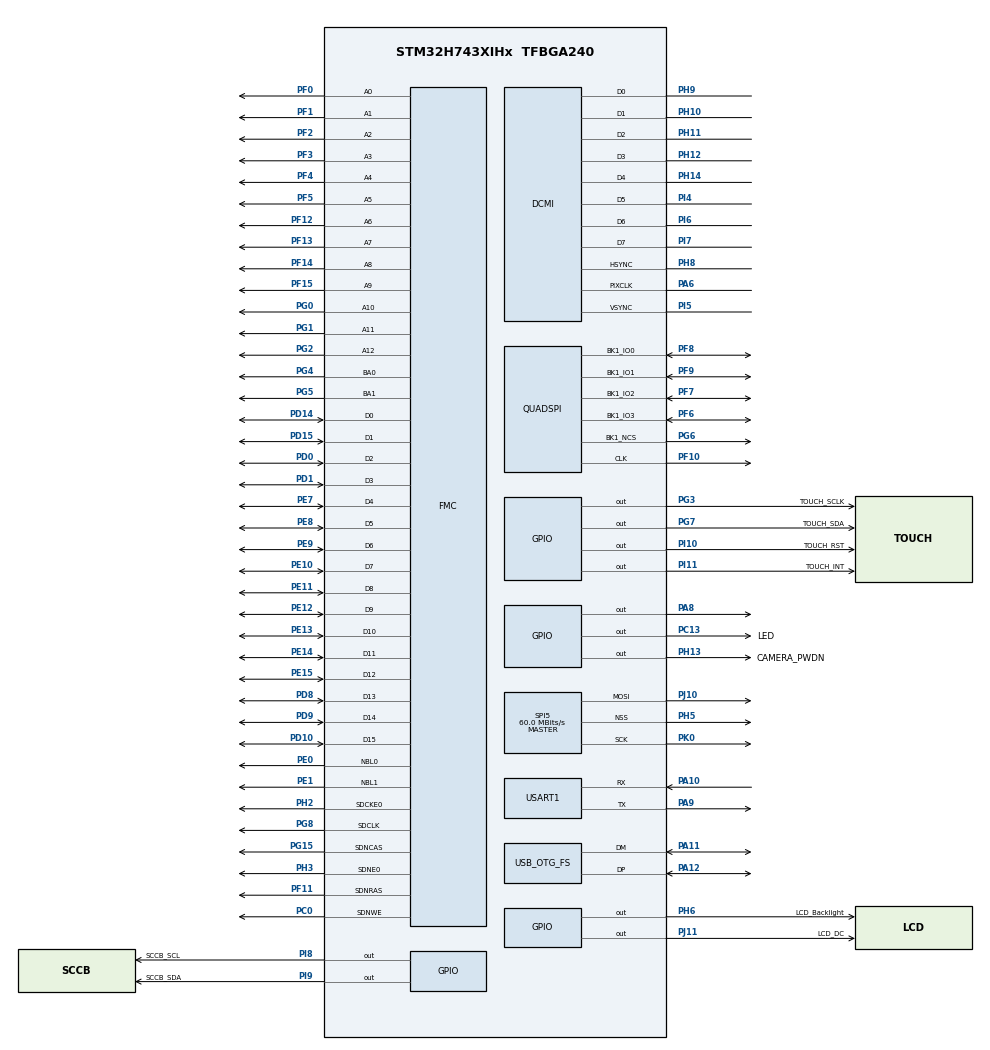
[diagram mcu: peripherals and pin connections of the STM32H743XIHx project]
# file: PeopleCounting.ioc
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ADC3.Channel-1\#ChannelRegularConversion=ADC_CHANNEL_VBAT
ADC3.Channel-2\#ChannelRegularConversion=ADC_CHANNEL_TEMPSENSOR
ADC3.Channel-3\#ChannelRegularConversion=ADC_CHANNEL_VREFINT
ADC3.ContinuousConvMode=ENABLE
ADC3.ConversionDataManagement=ADC_CONVERSIONDATA_DMA_CIRCULAR
ADC3.EOCSelection=ADC_EOC_SEQ_CONV
ADC3.EnableRegularConversion=ENABLE
ADC3.LeftBitShift=ADC_LEFTBITSHIFT_NONE
ADC3.NbrOfConversion=3
ADC3.NbrOfConversionFlag=1
ADC3.OffsetNumber-1\#ChannelRegularConversion=ADC_OFFSET_NONE
ADC3.OffsetNumber-2\#ChannelRegularConversion=ADC_OFFSET_NONE
ADC3.OffsetNumber-3\#ChannelRegularConversion=ADC_OFFSET_NONE
ADC3.OffsetSignedSaturation-1\#ChannelRegularConversion=DISABLE
ADC3.OffsetSignedSaturation-2\#ChannelRegularConversion=DISABLE
ADC3.OffsetSignedSaturation-3\#ChannelRegularConversion=DISABLE
ADC3.OversamplingMode=ENABLE
ADC3.Rank-1\#ChannelRegularConversion=1
ADC3.Rank-2\#ChannelRegularConversion=2
ADC3.Rank-3\#ChannelRegularConversion=3
ADC3.Ratio=1024
ADC3.Resolution=ADC_RESOLUTION_16B
ADC3.RightBitShift=ADC_RIGHTBITSHIFT_10
ADC3.SamplingTime-1\#ChannelRegularConversion=ADC_SAMPLETIME_810CYCLES_5
ADC3.SamplingTime-2\#ChannelRegularConversion=ADC_SAMPLETIME_810CYCLES_5
ADC3.SamplingTime-3\#ChannelRegularConversion=ADC_SAMPLETIME_810CYCLES_5
Bdma.ADC3.0.Direction=DMA_PERIPH_TO_MEMORY
Bdma.ADC3.0.EventEnable=DISABLE
Bdma.ADC3.0.Instance=BDMA_Channel0
Bdma.ADC3.0.MemDataAlignment=DMA_MDATAALIGN_HALFWORD
Bdma.ADC3.0.MemInc=DMA_MINC_ENABLE
Bdma.ADC3.0.Mode=DMA_CIRCULAR
Bdma.ADC3.0.PeriphDataAlignment=DMA_PDATAALIGN_HALFWORD
Bdma.ADC3.0.PeriphInc=DMA_PINC_DISABLE
Bdma.ADC3.0.Polarity=HAL_DMAMUX_REQ_GEN_RISING
Bdma.ADC3.0.Priority=DMA_PRIORITY_LOW
Bdma.ADC3.0.RequestNumber=1
Bdma.ADC3.0.SignalID=NONE
Bdma.ADC3.0.SyncEnable=DISABLE
Bdma.ADC3.0.SyncPolarity=HAL_DMAMUX_SYNC_NO_EVENT
Bdma.ADC3.0.SyncRequestNumber=1
Bdma.ADC3.0.SyncSignalID=NONE
Bdma.Request0=ADC3
Bdma.RequestsNb=1
CORTEX_M7.AccessPermission-Cortex_Memory_Protection_Unit_Region0_Settings=MPU_REGION_FULL_ACCESS
CORTEX_M7.AccessPermission-Cortex_Memory_Protection_Unit_Region1_Settings=MPU_REGION_FULL_ACCESS
CORTEX_M7.AccessPermission-Cortex_Memory_Protection_Unit_Region2_Settings=MPU_REGION_FULL_ACCESS
CORTEX_M7.AccessPermission-Cortex_Memory_Protection_Unit_Region3_Settings=MPU_REGION_FULL_ACCESS
CORTEX_M7.AccessPermission-Cortex_Memory_Protection_Unit_Region4_Settings=MPU_REGION_FULL_ACCESS
CORTEX_M7.AccessPermission-Cortex_Memory_Protection_Unit_Region5_Settings=MPU_REGION_FULL_ACCESS
CORTEX_M7.AccessPermission-Cortex_Memory_Protection_Unit_Region6_Settings=MPU_REGION_FULL_ACCESS
CORTEX_M7.AccessPermission-Cortex_Memory_Protection_Unit_Region7_Settings=MPU_REGION_FULL_ACCESS
CORTEX_M7.BaseAddress-Cortex_Memory_Protection_Unit_Region0_Settings=0x20000000
CORTEX_M7.BaseAddress-Cortex_Memory_Protection_Unit_Region1_Settings=0x24000000
CORTEX_M7.BaseAddress-Cortex_Memory_Protection_Unit_Region2_Settings=0x30000000
CORTEX_M7.BaseAddress-Cortex_Memory_Protection_Unit_Region3_Settings=0x38000000
CORTEX_M7.BaseAddress-Cortex_Memory_Protection_Unit_Region5_Settings=0xC0000000
CORTEX_M7.BaseAddress-Cortex_Memory_Protection_Unit_Region6_Settings=0x08000000
CORTEX_M7.BaseAddress-Cortex_Memory_Protection_Unit_Region7_Settings=0x90000000
CORTEX_M7.CPU_DCache=Enabled
CORTEX_M7.CPU_ICache=Enabled
CORTEX_M7.DisableExec-Cortex_Memory_Protection_Unit_Region5_Settings=MPU_INSTRUCTION_ACCESS_ENABLE
CORTEX_M7.Enable-Cortex_Memory_Protection_Unit_Region0_Settings=MPU_REGION_ENABLE
CORTEX_M7.Enable-Cortex_Memory_Protection_Unit_Region1_Settings=MPU_REGION_ENABLE
CORTEX_M7.Enable-Cortex_Memory_Protection_Unit_Region2_Settings=MPU_REGION_ENABLE
CORTEX_M7.Enable-Cortex_Memory_Protection_Unit_Region3_Settings=MPU_REGION_ENABLE
CORTEX_M7.Enable-Cortex_Memory_Protection_Unit_Region4_Settings=MPU_REGION_ENABLE
CORTEX_M7.Enable-Cortex_Memory_Protection_Unit_Region5_Settings=MPU_REGION_ENABLE
CORTEX_M7.Enable-Cortex_Memory_Protection_Unit_Region6_Settings=MPU_REGION_ENABLE
CORTEX_M7.Enable-Cortex_Memory_Protection_Unit_Region7_Settings=MPU_REGION_ENABLE
CORTEX_M7.IsBufferable-Cortex_Memory_Protection_Unit_Region0_Settings=MPU_ACCESS_BUFFERABLE
CORTEX_M7.IsBufferable-Cortex_Memory_Protection_Unit_Region1_Settings=MPU_ACCESS_BUFFERABLE
CORTEX_M7.IsBufferable-Cortex_Memory_Protection_Unit_Region2_Settings=MPU_ACCESS_BUFFERABLE
CORTEX_M7.IsBufferable-Cortex_Memory_Protection_Unit_Region3_Settings=MPU_ACCESS_BUFFERABLE
CORTEX_M7.IsBufferable-Cortex_Memory_Protection_Unit_Region4_Settings=MPU_ACCESS_BUFFERABLE
CORTEX_M7.IsBufferable-Cortex_Memory_Protection_Unit_Region5_Settings=MPU_ACCESS_BUFFERABLE
CORTEX_M7.IsBufferable-Cortex_Memory_Protection_Unit_Region6_Settings=MPU_ACCESS_BUFFERABLE
CORTEX_M7.IsBufferable-Cortex_Memory_Protection_Unit_Region7_Settings=MPU_ACCESS_BUFFERABLE
CORTEX_M7.IsCacheable-Cortex_Memory_Protection_Unit_Region0_Settings=MPU_ACCESS_CACHEABLE
CORTEX_M7.IsCacheable-Cortex_Memory_Protection_Unit_Region1_Settings=MPU_ACCESS_CACHEABLE
CORTEX_M7.IsCacheable-Cortex_Memory_Protection_Unit_Region2_Settings=MPU_ACCESS_CACHEABLE
CORTEX_M7.IsCacheable-Cortex_Memory_Protection_Unit_Region3_Settings=MPU_ACCESS_CACHEABLE
CORTEX_M7.IsCacheable-Cortex_Memory_Protection_Unit_Region4_Settings=MPU_ACCESS_CACHEABLE
CORTEX_M7.IsCacheable-Cortex_Memory_Protection_Unit_Region5_Settings=MPU_ACCESS_CACHEABLE
CORTEX_M7.IsCacheable-Cortex_Memory_Protection_Unit_Region6_Settings=MPU_ACCESS_CACHEABLE
CORTEX_M7.IsCacheable-Cortex_Memory_Protection_Unit_Region7_Settings=MPU_ACCESS_CACHEABLE
CORTEX_M7.IsShareable-Cortex_Memory_Protection_Unit_Region0_Settings=MPU_ACCESS_NOT_SHAREABLE
CORTEX_M7.IsShareable-Cortex_Memory_Protection_Unit_Region1_Settings=MPU_ACCESS_NOT_SHAREABLE
CORTEX_M7.IsShareable-Cortex_Memory_Protection_Unit_Region2_Settings=MPU_ACCESS_NOT_SHAREABLE
CORTEX_M7.IsShareable-Cortex_Memory_Protection_Unit_Region3_Settings=MPU_ACCESS_NOT_SHAREABLE
CORTEX_M7.IsShareable-Cortex_Memory_Protection_Unit_Region4_Settings=MPU_ACCESS_NOT_SHAREABLE
CORTEX_M7.IsShareable-Cortex_Memory_Protection_Unit_Region5_Settings=MPU_ACCESS_NOT_SHAREABLE
CORTEX_M7.IsShareable-Cortex_Memory_Protection_Unit_Region6_Settings=MPU_ACCESS_NOT_SHAREABLE
CORTEX_M7.IsShareable-Cortex_Memory_Protection_Unit_Region7_Settings=MPU_ACCESS_NOT_SHAREABLE
CORTEX_M7.MPU_Control=MPU_PRIVILEGED_DEFAULT
CORTEX_M7.Size-Cortex_Memory_Protection_Unit_Region0_Settings=MPU_REGION_SIZE_128KB
CORTEX_M7.Size-Cortex_Memory_Protection_Unit_Region1_Settings=MPU_REGION_SIZE_512KB
CORTEX_M7.Size-Cortex_Memory_Protection_Unit_Region2_Settings=MPU_REGION_SIZE_512KB
CORTEX_M7.Size-Cortex_Memory_Protection_Unit_Region3_Settings=MPU_REGION_SIZE_64KB
CORTEX_M7.Size-Cortex_Memory_Protection_Unit_Region4_Settings=MPU_REGION_SIZE_64KB
CORTEX_M7.Size-Cortex_Memory_Protection_Unit_Region5_Settings=MPU_REGION_SIZE_32MB
CORTEX_M7.Size-Cortex_Memory_Protection_Unit_Region6_Settings=MPU_REGION_SIZE_2MB
CORTEX_M7.Size-Cortex_Memory_Protection_Unit_Region7_Settings=MPU_REGION_SIZE_8MB
CORTEX_M7.default_mode_Activation=0
DCMI.ByteSelectMode=DCMI_BSM_ALL
DCMI.CaptureRate=DCMI_CR_ALTERNATE_4_FRAME
DCMI.JPEGMode=DCMI_JPEG_DISABLE
DCMI.LineSelectMode=DCMI_LSM_ALL
DCMI.PCKPolarity=DCMI_PCKPOLARITY_RISING
DMA2D.AlphaModeForeground=DMA2D_NO_MODIF_ALPHA
DMA2D.ChromaSubSamplingForeground=DMA2D_NO_CSS
DMA2D.ColorMode=DMA2D_OUTPUT_RGB565
DMA2D.InputAlphaForeground=255
DMA2D.InputColorModeForeground=DMA2D_INPUT_YCBCR
DMA2D.Mode=DMA2D_M2M_PFC
Dma.DCMI.0.Direction=DMA_PERIPH_TO_MEMORY
Dma.DCMI.0.EventEnable=DISABLE
Dma.DCMI.0.FIFOMode=DMA_FIFOMODE_ENABLE
Dma.DCMI.0.FIFOThreshold=DMA_FIFO_THRESHOLD_FULL
Dma.DCMI.0.Instance=DMA2_Stream0
Dma.DCMI.0.MemBurst=DMA_MBURST_INC4
Dma.DCMI.0.MemDataAlignment=DMA_MDATAALIGN_WORD
Dma.DCMI.0.MemInc=DMA_MINC_ENABLE
Dma.DCMI.0.Mode=DMA_CIRCULAR
Dma.DCMI.0.PeriphBurst=DMA_PBURST_SINGLE
Dma.DCMI.0.PeriphDataAlignment=DMA_PDATAALIGN_WORD
Dma.DCMI.0.PeriphInc=DMA_PINC_DISABLE
Dma.DCMI.0.Polarity=HAL_DMAMUX_REQ_GEN_RISING
Dma.DCMI.0.Priority=DMA_PRIORITY_VERY_HIGH
Dma.DCMI.0.RequestNumber=1
Dma.DCMI.0.SignalID=NONE
Dma.DCMI.0.SyncEnable=DISABLE
Dma.DCMI.0.SyncPolarity=HAL_DMAMUX_SYNC_NO_EVENT
Dma.DCMI.0.SyncRequestNumber=1
Dma.DCMI.0.SyncSignalID=NONE
Dma.MEMTOMEM.4.Direction=DMA_MEMORY_TO_MEMORY
Dma.MEMTOMEM.4.EventEnable=DISABLE
Dma.MEMTOMEM.4.FIFOMode=DMA_FIFOMODE_ENABLE
Dma.MEMTOMEM.4.FIFOThreshold=DMA_FIFO_THRESHOLD_FULL
Dma.MEMTOMEM.4.Instance=DMA1_Stream0
Dma.MEMTOMEM.4.MemBurst=DMA_MBURST_SINGLE
Dma.MEMTOMEM.4.MemDataAlignment=DMA_MDATAALIGN_WORD
Dma.MEMTOMEM.4.MemInc=DMA_MINC_ENABLE
Dma.MEMTOMEM.4.Mode=DMA_NORMAL
Dma.MEMTOMEM.4.PeriphBurst=DMA_PBURST_SINGLE
Dma.MEMTOMEM.4.PeriphDataAlignment=DMA_PDATAALIGN_WORD
Dma.MEMTOMEM.4.PeriphInc=DMA_PINC_ENABLE
Dma.MEMTOMEM.4.Polarity=HAL_DMAMUX_REQ_GEN_RISING
Dma.MEMTOMEM.4.Priority=DMA_PRIORITY_LOW
Dma.MEMTOMEM.4.RequestNumber=1
Dma.MEMTOMEM.4.SignalID=NONE
Dma.MEMTOMEM.4.SyncEnable=DISABLE
Dma.MEMTOMEM.4.SyncPolarity=HAL_DMAMUX_SYNC_NO_EVENT
Dma.MEMTOMEM.4.SyncRequestNumber=1
Dma.MEMTOMEM.4.SyncSignalID=NONE
Dma.Request0=DCMI
Dma.Request1=SPI5_TX
Dma.Request2=USART1_RX
Dma.Request3=USART1_TX
Dma.Request4=MEMTOMEM
Dma.SPI5_TX.1.Direction=DMA_MEMORY_TO_PERIPH
Dma.SPI5_TX.1.EventEnable=DISABLE
Dma.SPI5_TX.1.FIFOMode=DMA_FIFOMODE_ENABLE
Dma.SPI5_TX.1.FIFOThreshold=DMA_FIFO_THRESHOLD_FULL
Dma.SPI5_TX.1.Instance=DMA1_Stream3
Dma.SPI5_TX.1.MemBurst=DMA_MBURST_SINGLE
Dma.SPI5_TX.1.MemDataAlignment=DMA_MDATAALIGN_HALFWORD
Dma.SPI5_TX.1.MemInc=DMA_MINC_ENABLE
Dma.SPI5_TX.1.Mode=DMA_NORMAL
Dma.SPI5_TX.1.PeriphBurst=DMA_PBURST_SINGLE
Dma.SPI5_TX.1.PeriphDataAlignment=DMA_PDATAALIGN_HALFWORD
Dma.SPI5_TX.1.PeriphInc=DMA_PINC_DISABLE
Dma.SPI5_TX.1.Polarity=HAL_DMAMUX_REQ_GEN_RISING
Dma.SPI5_TX.1.Priority=DMA_PRIORITY_MEDIUM
Dma.SPI5_TX.1.RequestNumber=1
Dma.SPI5_TX.1.SignalID=NONE
Dma.SPI5_TX.1.SyncEnable=DISABLE
Dma.SPI5_TX.1.SyncPolarity=HAL_DMAMUX_SYNC_NO_EVENT
Dma.SPI5_TX.1.SyncRequestNumber=1
Dma.SPI5_TX.1.SyncSignalID=NONE
Dma.USART1_RX.2.Direction=DMA_PERIPH_TO_MEMORY
Dma.USART1_RX.2.EventEnable=DISABLE
Dma.USART1_RX.2.FIFOMode=DMA_FIFOMODE_DISABLE
Dma.USART1_RX.2.Instance=DMA1_Stream1
Dma.USART1_RX.2.MemDataAlignment=DMA_MDATAALIGN_BYTE
Dma.USART1_RX.2.MemInc=DMA_MINC_ENABLE
Dma.USART1_RX.2.Mode=DMA_NORMAL
Dma.USART1_RX.2.PeriphDataAlignment=DMA_PDATAALIGN_BYTE
Dma.USART1_RX.2.PeriphInc=DMA_PINC_DISABLE
Dma.USART1_RX.2.Polarity=HAL_DMAMUX_REQ_GEN_RISING
Dma.USART1_RX.2.Priority=DMA_PRIORITY_HIGH
Dma.USART1_RX.2.RequestNumber=1
Dma.USART1_RX.2.SignalID=NONE
Dma.USART1_RX.2.SyncEnable=DISABLE
Dma.USART1_RX.2.SyncPolarity=HAL_DMAMUX_SYNC_NO_EVENT
Dma.USART1_RX.2.SyncRequestNumber=1
Dma.USART1_RX.2.SyncSignalID=NONE
Dma.USART1_TX.3.Direction=DMA_MEMORY_TO_PERIPH
Dma.USART1_TX.3.EventEnable=DISABLE
Dma.USART1_TX.3.FIFOMode=DMA_FIFOMODE_DISABLE
Dma.USART1_TX.3.Instance=DMA1_Stream2
Dma.USART1_TX.3.MemDataAlignment=DMA_MDATAALIGN_BYTE
Dma.USART1_TX.3.MemInc=DMA_MINC_ENABLE
Dma.USART1_TX.3.Mode=DMA_NORMAL
Dma.USART1_TX.3.PeriphDataAlignment=DMA_PDATAALIGN_BYTE
Dma.USART1_TX.3.PeriphInc=DMA_PINC_DISABLE
Dma.USART1_TX.3.Polarity=HAL_DMAMUX_REQ_GEN_RISING
Dma.USART1_TX.3.Priority=DMA_PRIORITY_HIGH
Dma.USART1_TX.3.RequestNumber=1
Dma.USART1_TX.3.SignalID=NONE
Dma.USART1_TX.3.SyncEnable=DISABLE
Dma.USART1_TX.3.SyncPolarity=HAL_DMAMUX_SYNC_NO_EVENT
Dma.USART1_TX.3.SyncRequestNumber=1
Dma.USART1_TX.3.SyncSignalID=NONE
FMC.BankMapConfig=FMC_SWAPBMAP_DISABLE
FMC.CASLatency1=FMC_SDRAM_CAS_LATENCY_3
FMC.ColumnBitsNumber1=FMC_SDRAM_COLUMN_BITS_NUM_9
FMC.ExitSelfRefreshDelay1=7
FMC.LoadToActiveDelay1=2
FMC.RCDDelay1=2
FMC.RPDelay1=2
FMC.RPDelay2=2
FMC.ReadBurst1=FMC_SDRAM_RBURST_ENABLE
FMC.ReadBurst2=FMC_SDRAM_RBURST_ENABLE
FMC.ReadPipeDelay1=FMC_SDRAM_RPIPE_DELAY_1
FMC.ReadPipeDelay2=FMC_SDRAM_RPIPE_DELAY_1
FMC.RowCycleDelay1=7
FMC.RowCycleDelay2=7
FMC.SDClockPeriod1=FMC_SDRAM_CLOCK_PERIOD_2
FMC.SDClockPeriod2=FMC_SDRAM_CLOCK_PERIOD_2
FMC.SelfRefreshTime1=4
FMC.WriteRecoveryTime1=3
FREERTOS.Tasks01=defaultTask,24,128,StartDefaultTask,Default,NULL,Dynamic,NULL,NULL;LCDRefresh,24,256,LCDRefreshTask,Default,NULL,Dynamic,NULL,NULL;LEDToggle,24,128,LEDToggleTask,Default,NULL,Dynamic,NULL,NULL;ImageProcess,24,1024,ImageProcessTask,Default,NULL,Dynamic,NULL,NULL;ObjectDetect,24,2048,ObjectDetectTask,Default,NULL,Dynamic,NULL,NULL;ADCSampling,24,128,ADCSamplingTask,Default,NULL,Dynamic,NULL,NULL
FREERTOS.configENABLE_FPU=1
FREERTOS.configGENERATE_RUN_TIME_STATS=1
FREERTOS.configRECORD_STACK_HIGH_ADDRESS=1
FREERTOS.configTOTAL_HEAP_SIZE=16384
FREERTOS.configUSE_STATS_FORMATTING_FUNCTIONS=1
JPEG.JPEG_RGB_FORMAT=JPEG_RGB565
Mcu.Family=STM32H7
Mcu.Name=STM32H743XIHx
Mcu.Package=TFBGA240
Mdma.MDMA_Channel1.JPEG_INFIFO_TH.0.BlockCount=0
Mdma.MDMA_Channel1.JPEG_INFIFO_TH.0.BlockDataLength=0
Mdma.MDMA_Channel1.JPEG_INFIFO_TH.0.BufferTransferLength=32
Mdma.MDMA_Channel1.JPEG_INFIFO_TH.0.CircularMode=MDMA_LINEAR_LIST
Mdma.MDMA_Channel1.JPEG_INFIFO_TH.0.DataAlignment=MDMA_DATAALIGN_PACKENABLE
Mdma.MDMA_Channel1.JPEG_INFIFO_TH.0.DestBlockAddressOffset=0
Mdma.MDMA_Channel1.JPEG_INFIFO_TH.0.DestBurst=MDMA_DEST_BURST_SINGLE
Mdma.MDMA_Channel1.JPEG_INFIFO_TH.0.DestDataSize=MDMA_DEST_DATASIZE_WORD
Mdma.MDMA_Channel1.JPEG_INFIFO_TH.0.DestinationInc=MDMA_DEST_INC_DISABLE
Mdma.MDMA_Channel1.JPEG_INFIFO_TH.0.DstAddress=0
Mdma.MDMA_Channel1.JPEG_INFIFO_TH.0.Endianness=MDMA_LITTLE_ENDIANNESS_PRESERVE
Mdma.MDMA_Channel1.JPEG_INFIFO_TH.0.Instance=MDMA_Channel1
Mdma.MDMA_Channel1.JPEG_INFIFO_TH.0.MaskAddress=0
Mdma.MDMA_Channel1.JPEG_INFIFO_TH.0.MaskData=0
Mdma.MDMA_Channel1.JPEG_INFIFO_TH.0.Priority=MDMA_PRIORITY_LOW
Mdma.MDMA_Channel1.JPEG_INFIFO_TH.0.Rank=First
Mdma.MDMA_Channel1.JPEG_INFIFO_TH.0.SourceBlockAddressOffset=0
Mdma.MDMA_Channel1.JPEG_INFIFO_TH.0.SourceBurst=MDMA_SOURCE_BURST_SINGLE
Mdma.MDMA_Channel1.JPEG_INFIFO_TH.0.SourceDataSize=MDMA_SRC_DATASIZE_BYTE
Mdma.MDMA_Channel1.JPEG_INFIFO_TH.0.SourceInc=MDMA_SRC_INC_BYTE
Mdma.MDMA_Channel1.JPEG_INFIFO_TH.0.SrcAddress=0
Mdma.MDMA_Channel1.JPEG_INFIFO_TH.0.TransferTriggerMode=MDMA_BUFFER_TRANSFER
Mdma.MDMA_Channel1.Request0=JPEG_INFIFO_TH
Mdma.MDMA_Channel1.RequestsNb=1
Mdma.MDMA_Channel2.JPEG_OUTFIFO_TH.0.BlockCount=0
Mdma.MDMA_Channel2.JPEG_OUTFIFO_TH.0.BlockDataLength=0
Mdma.MDMA_Channel2.JPEG_OUTFIFO_TH.0.BufferTransferLength=32
Mdma.MDMA_Channel2.JPEG_OUTFIFO_TH.0.CircularMode=MDMA_LINEAR_LIST
Mdma.MDMA_Channel2.JPEG_OUTFIFO_TH.0.DataAlignment=MDMA_DATAALIGN_PACKENABLE
Mdma.MDMA_Channel2.JPEG_OUTFIFO_TH.0.DestBlockAddressOffset=0
Mdma.MDMA_Channel2.JPEG_OUTFIFO_TH.0.DestBurst=MDMA_DEST_BURST_SINGLE
Mdma.MDMA_Channel2.JPEG_OUTFIFO_TH.0.DestDataSize=MDMA_DEST_DATASIZE_BYTE
Mdma.MDMA_Channel2.JPEG_OUTFIFO_TH.0.DestinationInc=MDMA_DEST_INC_BYTE
Mdma.MDMA_Channel2.JPEG_OUTFIFO_TH.0.DstAddress=0
Mdma.MDMA_Channel2.JPEG_OUTFIFO_TH.0.Endianness=MDMA_LITTLE_ENDIANNESS_PRESERVE
Mdma.MDMA_Channel2.JPEG_OUTFIFO_TH.0.Instance=MDMA_Channel2
Mdma.MDMA_Channel2.JPEG_OUTFIFO_TH.0.MaskAddress=0
Mdma.MDMA_Channel2.JPEG_OUTFIFO_TH.0.MaskData=0
Mdma.MDMA_Channel2.JPEG_OUTFIFO_TH.0.Priority=MDMA_PRIORITY_LOW
Mdma.MDMA_Channel2.JPEG_OUTFIFO_TH.0.Rank=First
Mdma.MDMA_Channel2.JPEG_OUTFIFO_TH.0.SourceBlockAddressOffset=0
Mdma.MDMA_Channel2.JPEG_OUTFIFO_TH.0.SourceBurst=MDMA_SOURCE_BURST_SINGLE
Mdma.MDMA_Channel2.JPEG_OUTFIFO_TH.0.SourceDataSize=MDMA_SRC_DATASIZE_WORD
Mdma.MDMA_Channel2.JPEG_OUTFIFO_TH.0.SourceInc=MDMA_SRC_INC_DISABLE
Mdma.MDMA_Channel2.JPEG_OUTFIFO_TH.0.SrcAddress=0
Mdma.MDMA_Channel2.JPEG_OUTFIFO_TH.0.TransferTriggerMode=MDMA_BUFFER_TRANSFER
Mdma.MDMA_Channel2.Request0=JPEG_OUTFIFO_TH
Mdma.MDMA_Channel2.RequestsNb=1
Mdma.RequestSet0=MDMA_Channel1
Mdma.RequestSet1=MDMA_Channel2
Mdma.RequestSetsNb=2
NVIC.DCMI_IRQn=true\:5\:0\:false\:false\:true\:true\:true\:true\:true
NVIC.DMA1_Stream0_IRQn=true\:5\:0\:false\:false\:true\:true\:true\:true\:true
NVIC.DMA1_Stream1_IRQn=true\:5\:0\:false\:false\:true\:true\:true\:true\:true
NVIC.DMA1_Stream2_IRQn=true\:5\:0\:false\:false\:true\:true\:true\:true\:true
NVIC.DMA1_Stream3_IRQn=true\:5\:0\:false\:false\:true\:true\:true\:true\:true
NVIC.DMA2D_IRQn=true\:5\:0\:false\:false\:true\:true\:true\:true\:true
NVIC.DMA2_Stream0_IRQn=true\:5\:0\:false\:false\:true\:true\:true\:true\:true
NVIC.JPEG_IRQn=true\:5\:0\:false\:false\:true\:true\:true\:true\:true
NVIC.MDMA_IRQn=true\:5\:0\:false\:false\:true\:true\:true\:true\:true
NVIC.OTG_FS_IRQn=true\:5\:0\:false\:false\:true\:true\:false\:true\:true
NVIC.PriorityGroup=NVIC_PRIORITYGROUP_4
NVIC.RCC_IRQn=true\:5\:0\:false\:false\:true\:true\:true\:false\:true
NVIC.SPI5_IRQn=true\:5\:0\:true\:false\:true\:true\:false\:true\:true
NVIC.TIM6_DAC_IRQn=true\:15\:0\:true\:false\:true\:false\:false\:true\:true
NVIC.TimeBase=TIM6_DAC_IRQn
NVIC.TimeBaseIP=TIM6
NVIC.USART1_IRQn=true\:5\:0\:false\:false\:true\:true\:true\:true\:true
PA10.GPIO_Speed=GPIO_SPEED_FREQ_VERY_HIGH
PA10.Mode=Asynchronous
PA10.Signal=USART1_RX
PA11.GPIO_Speed=GPIO_SPEED_FREQ_VERY_HIGH
PA11.Mode=Device_Only
PA11.Signal=USB_OTG_FS_DM
PA12.GPIO_Speed=GPIO_SPEED_FREQ_VERY_HIGH
PA12.Mode=Device_Only
PA12.Signal=USB_OTG_FS_DP
PA13\ (JTMS/SWDIO).Mode=Serial_Wire
PA13\ (JTMS/SWDIO).Signal=DEBUG_JTMS-SWDIO
PA14\ (JTCK/SWCLK).Mode=Serial_Wire
PA14\ (JTCK/SWCLK).Signal=DEBUG_JTCK-SWCLK
PA6.GPIO_Speed=GPIO_SPEED_FREQ_VERY_HIGH
PA6.Mode=Slave_8_bits_External_Synchro
PA6.Signal=DCMI_PIXCLK
PA8.Signal=GPIO_Output
PA9.GPIO_Speed=GPIO_SPEED_FREQ_VERY_HIGH
PA9.Mode=Asynchronous
PA9.Signal=USART1_TX
PC0.Signal=FMC_SDNWE
PC10.Signal=SDMMC1_D2
PC11.Signal=SDMMC1_D3
PC12.Signal=SDMMC1_CK
PC13.GPIO_Label=LED
PC13.Signal=GPIO_Output
PC14-OSC32_IN\ (OSC32_IN).Mode=LSE-External-Oscillator
PC14-OSC32_IN\ (OSC32_IN).Signal=RCC_OSC32_IN
PC15-OSC32_OUT\ (OSC32_OUT).Mode=LSE-External-Oscillator
PC15-OSC32_OUT\ (OSC32_OUT).Signal=RCC_OSC32_OUT
PC8.Signal=SDMMC1_D0
PC9.Signal=SDMMC1_D1
PD0.Signal=FMC_D2_DA2
PD1.Signal=FMC_D3_DA3
PD10.Signal=FMC_D15_DA15
PD14.Signal=FMC_D0_DA0
PD15.Signal=FMC_D1_DA1
PD2.Signal=SDMMC1_CMD
PD8.Signal=FMC_D13_DA13
PD9.Signal=FMC_D14_DA14
PE0.Signal=FMC_NBL0
PE1.Signal=FMC_NBL1
PE10.Signal=FMC_D7_DA7
PE11.Signal=FMC_D8_DA8
PE12.Signal=FMC_D9_DA9
PE13.Signal=FMC_D10_DA10
PE14.Signal=FMC_D11_DA11
PE15.Signal=FMC_D12_DA12
PE7.Signal=FMC_D4_DA4
PE8.Signal=FMC_D5_DA5
PE9.Signal=FMC_D6_DA6
PF0.Signal=FMC_A0
PF1.Signal=FMC_A1
PF10.GPIO_Speed=GPIO_SPEED_FREQ_VERY_HIGH
PF10.Mode=Single Bank 1
PF10.Signal=QUADSPI_CLK
PF11.Signal=FMC_SDNRAS
PF12.Signal=FMC_A6
PF13.Signal=FMC_A7
PF14.Signal=FMC_A8
PF15.Signal=FMC_A9
PF2.Signal=FMC_A2
PF3.Signal=FMC_A3
PF4.Signal=FMC_A4
PF5.Signal=FMC_A5
PF6.GPIO_Speed=GPIO_SPEED_FREQ_VERY_HIGH
PF6.Mode=Single Bank 1
PF6.Signal=QUADSPI_BK1_IO3
PF7.GPIO_Speed=GPIO_SPEED_FREQ_VERY_HIGH
PF7.Mode=Single Bank 1
PF7.Signal=QUADSPI_BK1_IO2
PF8.GPIO_Speed=GPIO_SPEED_FREQ_VERY_HIGH
PF8.Mode=Single Bank 1
PF8.Signal=QUADSPI_BK1_IO0
PF9.GPIO_Speed=GPIO_SPEED_FREQ_VERY_HIGH
PF9.Mode=Single Bank 1
PF9.Signal=QUADSPI_BK1_IO1
PG0.Signal=FMC_A10
PG1.Signal=FMC_A11
PG10.GPIO_Speed=GPIO_SPEED_FREQ_VERY_HIGH
PG10.Signal=LTDC_G3
PG15.Signal=FMC_SDNCAS
PG2.Signal=FMC_A12
PG3.GPIO_Label=TOUCH_SCLK
PG3.GPIO_ModeDefaultOutputPP=GPIO_MODE_OUTPUT_OD
PG3.GPIO_PuPd=GPIO_PULLUP
PG3.GPIO_Speed=GPIO_SPEED_FREQ_LOW
PG3.PinState=GPIO_PIN_SET
PG3.Signal=GPIO_Output
PG4.Signal=FMC_A14_BA0
PG5.Signal=FMC_A15_BA1
PG6.GPIO_Speed=GPIO_SPEED_FREQ_VERY_HIGH
PG6.Mode=Single Bank 1
PG6.Signal=QUADSPI_BK1_NCS
PG7.GPIO_Label=TOUCH_SDA
PG7.GPIO_ModeDefaultOutputPP=GPIO_MODE_OUTPUT_OD
PG7.GPIO_PuPd=GPIO_PULLUP
PG7.GPIO_Speed=GPIO_SPEED_FREQ_LOW
PG7.PinState=GPIO_PIN_SET
PG7.Signal=GPIO_Output
PG8.Signal=FMC_SDCLK
PH0-OSC_IN\ (PH0).Mode=HSE-External-Oscillator
PH0-OSC_IN\ (PH0).Signal=RCC_OSC_IN
PH1-OSC_OUT\ (PH1).Mode=HSE-External-Oscillator
PH1-OSC_OUT\ (PH1).Signal=RCC_OSC_OUT
PH10.GPIO_Speed=GPIO_SPEED_FREQ_VERY_HIGH
PH10.Mode=Slave_8_bits_External_Synchro
PH10.Signal=DCMI_D1
PH11.GPIO_Speed=GPIO_SPEED_FREQ_VERY_HIGH
PH11.Mode=Slave_8_bits_External_Synchro
PH11.Signal=DCMI_D2
PH12.GPIO_Speed=GPIO_SPEED_FREQ_VERY_HIGH
PH12.Mode=Slave_8_bits_External_Synchro
PH12.Signal=DCMI_D3
PH13.GPIO_Label=CAMERA_PWDN
PH13.GPIO_PuPd=GPIO_PULLUP
PH13.PinState=GPIO_PIN_SET
PH13.Signal=GPIO_Output
PH14.GPIO_Speed=GPIO_SPEED_FREQ_VERY_HIGH
PH14.Mode=Slave_8_bits_External_Synchro
PH14.Signal=DCMI_D4
PH15.GPIO_Speed=GPIO_SPEED_FREQ_VERY_HIGH
PH15.Signal=LTDC_G4
PH2.Mode=SdramChipSelect1_1
PH2.Signal=FMC_SDCKE0
PH3.Mode=SdramChipSelect1_1
PH3.Signal=FMC_SDNE0
PH4.GPIO_Speed=GPIO_SPEED_FREQ_VERY_HIGH
PH4.Signal=LTDC_G5
PH5.GPIO_Speed=GPIO_SPEED_FREQ_VERY_HIGH
PH5.Mode=NSS_Signal_Hard_Output
PH5.Signal=SPI5_NSS
PH6.GPIO_Label=LCD_Backlight
PH6.Signal=GPIO_Output
PH8.GPIO_Speed=GPIO_SPEED_FREQ_VERY_HIGH
PH8.Mode=Slave_8_bits_External_Synchro
PH8.Signal=DCMI_HSYNC
PH9.GPIO_Speed=GPIO_SPEED_FREQ_VERY_HIGH
PH9.Mode=Slave_8_bits_External_Synchro
PH9.Signal=DCMI_D0
PI10.GPIO_Label=TOUCH_RST
PI10.GPIO_PuPd=GPIO_PULLUP
PI10.PinState=GPIO_PIN_SET
PI10.Signal=GPIO_Output
PI11.GPIO_Label=TOUCH_INT
PI11.GPIO_PuPd=GPIO_PULLUP
PI11.Signal=GPIO_Output
PI12.GPIO_Speed=GPIO_SPEED_FREQ_VERY_HIGH
PI12.Signal=LTDC_HSYNC
PI13.GPIO_Speed=GPIO_SPEED_FREQ_VERY_HIGH
PI13.Signal=LTDC_VSYNC
PI14.GPIO_Speed=GPIO_SPEED_FREQ_VERY_HIGH
PI14.Signal=LTDC_CLK
PI15.GPIO_Speed=GPIO_SPEED_FREQ_VERY_HIGH
PI15.Signal=LTDC_R0
PI4.GPIO_Speed=GPIO_SPEED_FREQ_VERY_HIGH
PI4.Mode=Slave_8_bits_External_Synchro
PI4.Signal=DCMI_D5
PI5.GPIO_Speed=GPIO_SPEED_FREQ_VERY_HIGH
PI5.Mode=Slave_8_bits_External_Synchro
PI5.Signal=DCMI_VSYNC
PI6.GPIO_Speed=GPIO_SPEED_FREQ_VERY_HIGH
PI6.Mode=Slave_8_bits_External_Synchro
PI6.Signal=DCMI_D6
PI7.GPIO_Speed=GPIO_SPEED_FREQ_VERY_HIGH
PI7.Mode=Slave_8_bits_External_Synchro
PI7.Signal=DCMI_D7
PI8.GPIO_Label=SCCB_SCL
PI8.GPIO_ModeDefaultOutputPP=GPIO_MODE_OUTPUT_OD
PI8.GPIO_PuPd=GPIO_PULLUP
PI8.PinState=GPIO_PIN_SET
PI8.Signal=GPIO_Output
PI9.GPIO_Label=SCCB_SDA
PI9.GPIO_ModeDefaultOutputPP=GPIO_MODE_OUTPUT_OD
PI9.GPIO_PuPd=GPIO_PULLUP
PI9.GPIO_Speed=GPIO_SPEED_FREQ_LOW
PI9.PinState=GPIO_PIN_SET
PI9.Signal=GPIO_Output
PJ0.GPIO_Speed=GPIO_SPEED_FREQ_VERY_HIGH
PJ0.Signal=LTDC_R1
PJ1.GPIO_Speed=GPIO_SPEED_FREQ_VERY_HIGH
PJ1.Signal=LTDC_R2
PJ10.GPIO_Speed=GPIO_SPEED_FREQ_VERY_HIGH
PJ10.Mode=TX_Only_Simplex_Unidirect_Master
PJ10.Signal=SPI5_MOSI
PJ11.GPIO_Label=LCD_DC
PJ11.GPIO_PuPd=GPIO_NOPULL
PJ11.Signal=GPIO_Output
PJ12.GPIO_Speed=GPIO_SPEED_FREQ_VERY_HIGH
PJ12.Signal=LTDC_B0
PJ13.GPIO_Speed=GPIO_SPEED_FREQ_VERY_HIGH
PJ13.Signal=LTDC_B1
PJ14.GPIO_Speed=GPIO_SPEED_FREQ_VERY_HIGH
PJ14.Signal=LTDC_B2
PJ15.GPIO_Speed=GPIO_SPEED_FREQ_VERY_HIGH
PJ15.Signal=LTDC_B3
PJ2.GPIO_Speed=GPIO_SPEED_FREQ_VERY_HIGH
PJ2.Signal=LTDC_R3
PJ3.GPIO_Speed=GPIO_SPEED_FREQ_VERY_HIGH
PJ3.Signal=LTDC_R4
PJ4.GPIO_Speed=GPIO_SPEED_FREQ_VERY_HIGH
PJ4.Signal=LTDC_R5
PJ5.GPIO_Speed=GPIO_SPEED_FREQ_VERY_HIGH
PJ5.Signal=LTDC_R6
PJ6.GPIO_Speed=GPIO_SPEED_FREQ_VERY_HIGH
PJ6.Signal=LTDC_R7
PJ7.GPIO_Speed=GPIO_SPEED_FREQ_VERY_HIGH
PJ7.Signal=LTDC_G0
PJ8.GPIO_Speed=GPIO_SPEED_FREQ_VERY_HIGH
PJ8.Signal=LTDC_G1
PJ9.GPIO_Speed=GPIO_SPEED_FREQ_VERY_HIGH
PJ9.Signal=LTDC_G2
PK0.GPIO_Speed=GPIO_SPEED_FREQ_VERY_HIGH
PK0.Mode=TX_Only_Simplex_Unidirect_Master
PK0.Signal=SPI5_SCK
PK1.GPIO_Speed=GPIO_SPEED_FREQ_VERY_HIGH
PK1.Signal=LTDC_G6
PK2.GPIO_Speed=GPIO_SPEED_FREQ_VERY_HIGH
PK2.Signal=LTDC_G7
PK3.GPIO_Speed=GPIO_SPEED_FREQ_VERY_HIGH
PK3.Signal=LTDC_B4
PK4.GPIO_Speed=GPIO_SPEED_FREQ_VERY_HIGH
PK4.Signal=LTDC_B5
PK5.GPIO_Speed=GPIO_SPEED_FREQ_VERY_HIGH
PK5.Signal=LTDC_B6
PK6.GPIO_Speed=GPIO_SPEED_FREQ_VERY_HIGH
PK6.Signal=LTDC_B7
PK7.GPIO_Speed=GPIO_SPEED_FREQ_VERY_HIGH
PK7.Signal=LTDC_DE
ProjectManager.HeapSize=0x1000
ProjectManager.StackSize=0x3000
ProjectManager.TargetToolchain=CMake
QUADSPI.ClockMode=QSPI_CLOCK_MODE_3
QUADSPI.ClockPrescaler=1
QUADSPI.FifoThreshold=32
QUADSPI.FlashSize=22
QUADSPI.SampleShifting=QSPI_SAMPLE_SHIFTING_HALFCYCLE
RCC.ADCFreq_Value=100000000
RCC.APB1Freq_Value=120000000
RCC.APB2Freq_Value=120000000
RCC.APB3Freq_Value=120000000
RCC.APB4Freq_Value=120000000
RCC.CortexFreq_Value=480000000
RCC.D1PPRE=RCC_APB3_DIV2
RCC.D2PPRE1=RCC_APB1_DIV2
RCC.D2PPRE2=RCC_APB2_DIV2
RCC.D3PPRE=RCC_APB4_DIV2
RCC.DIVM1=5
RCC.DIVM2=5
RCC.DIVM3=5
RCC.DIVN1=192
RCC.DIVN2=100
RCC.DIVN3=144
RCC.DIVP2=5
RCC.DIVQ1=4
RCC.DIVQ2=5
RCC.DIVQ3=15
RCC.DIVR3=20
RCC.HCLKFreq_Value=240000000
RCC.HPRE=RCC_HCLK_DIV2
RCC.PLL2FRACN=0
RCC.PLLFRACN=0
RCC.PLLSourceVirtual=RCC_PLLSOURCE_HSE
RCC.RTCClockSelection=RCC_RTCCLKSOURCE_LSE
RCC.SDMMC1CLockSelection=RCC_SDMMCCLKSOURCE_PLL2
RCC.SYSCLKFreq_VALUE=480000000
RCC.SYSCLKSource=RCC_SYSCLKSOURCE_PLLCLK
RCC.USBCLockSelection=RCC_USBCLKSOURCE_PLL3
RCC.USBFreq_Value=48000000
SH.FMC_A0.0=FMC_A0,13b-sda1
SH.FMC_A1.0=FMC_A1,13b-sda1
SH.FMC_A10.0=FMC_A10,13b-sda1
SH.FMC_A11.0=FMC_A11,13b-sda1
SH.FMC_A12.0=FMC_A12,13b-sda1
SH.FMC_A14_BA0.0=FMC_BA0,FourSdramBanks1
SH.FMC_A15_BA1.0=FMC_BA1,FourSdramBanks1
SH.FMC_A2.0=FMC_A2,13b-sda1
SH.FMC_A3.0=FMC_A3,13b-sda1
SH.FMC_A4.0=FMC_A4,13b-sda1
SH.FMC_A5.0=FMC_A5,13b-sda1
SH.FMC_A6.0=FMC_A6,13b-sda1
SH.FMC_A7.0=FMC_A7,13b-sda1
SH.FMC_A8.0=FMC_A8,13b-sda1
SH.FMC_A9.0=FMC_A9,13b-sda1
SH.FMC_D0_DA0.0=FMC_D0,sd-16b-d1
SH.FMC_D10_DA10.0=FMC_D10,sd-16b-d1
SH.FMC_D11_DA11.0=FMC_D11,sd-16b-d1
SH.FMC_D12_DA12.0=FMC_D12,sd-16b-d1
SH.FMC_D13_DA13.0=FMC_D13,sd-16b-d1
SH.FMC_D14_DA14.0=FMC_D14,sd-16b-d1
SH.FMC_D15_DA15.0=FMC_D15,sd-16b-d1
SH.FMC_D1_DA1.0=FMC_D1,sd-16b-d1
SH.FMC_D2_DA2.0=FMC_D2,sd-16b-d1
SH.FMC_D3_DA3.0=FMC_D3,sd-16b-d1
SH.FMC_D4_DA4.0=FMC_D4,sd-16b-d1
SH.FMC_D5_DA5.0=FMC_D5,sd-16b-d1
SH.FMC_D6_DA6.0=FMC_D6,sd-16b-d1
SH.FMC_D7_DA7.0=FMC_D7,sd-16b-d1
SH.FMC_D8_DA8.0=FMC_D8,sd-16b-d1
SH.FMC_D9_DA9.0=FMC_D9,sd-16b-d1
SH.FMC_NBL0.0=FMC_NBL0,Sd2ByteEnable1
SH.FMC_NBL1.0=FMC_NBL1,Sd2ByteEnable1
SH.FMC_SDCLK.0=FMC_SDCLK,13b-sda1
SH.FMC_SDNCAS.0=FMC_SDNCAS,13b-sda1
SH.FMC_SDNRAS.0=FMC_SDNRAS,13b-sda1
SH.FMC_SDNWE.0=FMC_SDNWE,13b-sda1
SPI5.CalculateBaudRate=60.0 MBits/s
SPI5.DataSize=SPI_DATASIZE_8BIT
SPI5.Direction=SPI_DIRECTION_2LINES_TXONLY
SPI5.FifoThreshold=SPI_FIFO_THRESHOLD_02DATA
SPI5.Mode=SPI_MODE_MASTER
SPI5.NSSPMode=SPI_NSS_PULSE_DISABLE
SPI5.VirtualNSS=VM_NSSHARD
SPI5.VirtualType=VM_MASTER
STMicroelectronics.X-CUBE-ALGOBUILD.1.4.0.LibraryCcDSPOoLibraryJjDSPOoLibrary=true
USART1.VirtualMode-Asynchronous=VM_ASYNC
USB_DEVICE.CLASS_NAME_FS=CDC
USB_DEVICE.VirtualMode-CDC_FS=Cdc
USB_DEVICE.VirtualModeFS=Cdc_FS
USB_OTG_FS.VirtualMode=Device_Only
USB_OTG_FS.dma_enable=DISABLE
VP_ADC3_TempSens_Input.Mode=IN-TempSens
VP_ADC3_Vbat_Input.Mode=IN-Vbat
VP_ADC3_Vref_Input.Mode=IN-Vrefint
VP_DMA2D_VS_DMA2D.Mode=DMA2D_Activate
VP_FREERTOS_VS_CMSIS_V2.Mode=CMSIS_V2
VP_JPEG_VS_JPEG.Mode=JPEG_Activate
VP_MEMORYMAP_VS_MEMORYMAP.Mode=CurAppReg
VP_RTC_VS_RTC_Activate.Mode=RTC_Enabled
VP_RTC_VS_RTC_Calendar.Mode=RTC_Calendar
VP_STMicroelectronics.X-CUBE-ALGOBUILD_VS_DSPOoLibraryJjLibrary_1.4.0_1.4.0.Mode=DSPOoLibraryJjLibrary
VP_SYS_VS_tim6.Mode=TIM6
VP_USB_DEVICE_VS_USB_DEVICE_CDC_FS.Mode=CDC_FS
board=custom

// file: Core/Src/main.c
/* USER CODE BEGIN Header */
/**
  ******************************************************************************
  * @file           : main.c
  * @brief          : Main program body
  ******************************************************************************
  * @attention
  *
  * Copyright (c) 2026 STMicroelectronics.
  * All rights reserved.
  *
  * This software is licensed under terms that can be found in the LICENSE file
  * in the root directory of this software component.
  * If no LICENSE file comes with this software, it is provided AS-IS.
  *
  ******************************************************************************
  */
/* USER CODE END Header */
#include "main.h"
#include "FreeRTOS.h"
#include "cmsis_os2.h"
#include "adc.h"
#include "bdma.h"
#include "dcmi.h"
#include "dma.h"
#include "dma2d.h"
#include "jpeg.h"
#include "mdma.h"
#include "quadspi.h"
#include "rtc.h"
#include "spi.h"
#include "usart.h"
#include "usb_device.h"
#include "gpio.h"
#include "fmc.h"

/* USER CODE BEGIN Includes */

#include "MyCode.h"

/* USER CODE END Includes */

void SystemClock_Config(void);
static void MPU_Config(void);
void MX_FREERTOS_Init(void);

int main(void)
{

  /* MPU Configuration--------------------------------------------------------*/
  MPU_Config();

  /* Enable the CPU Cache */

  /* Enable I-Cache---------------------------------------------------------*/
  SCB_EnableICache();

  /* Enable D-Cache---------------------------------------------------------*/
  SCB_EnableDCache();

  /* MCU Configuration--------------------------------------------------------*/

  /* Reset of all peripherals, Initializes the Flash interface and the Systick. */
  HAL_Init();

  /* Configure the system clock */
  SystemClock_Config();

  /* Initialize all configured peripherals */
  MX_GPIO_Init();
  MX_DMA_Init();
  MX_MDMA_Init();
  MX_BDMA_Init();
  MX_DCMI_Init();
  MX_QUADSPI_Init();
  MX_FMC_Init();
  MX_USART1_UART_Init();
  MX_ADC3_Init();
  MX_SPI5_Init();
  MX_DMA2D_Init();
  MX_JPEG_Init();
  MX_RTC_Init();
  /* USER CODE BEGIN 2 */

  Setup();

  /* USER CODE END 2 */

  /* Init scheduler */
  osKernelInitialize();  /* Call init function for freertos objects (in cmsis_os2.c) */
  MX_FREERTOS_Init();

  /* Start scheduler */
  osKernelStart();

  /* We should never get here as control is now taken by the scheduler */

  /* Infinite loop */
  while (1)
  {

  }
}

void SystemClock_Config(void)
{
  RCC_OscInitTypeDef RCC_OscInitStruct = {0};
  RCC_ClkInitTypeDef RCC_ClkInitStruct = {0};

  /** Supply configuration update enable
  */
  HAL_PWREx_ConfigSupply(PWR_LDO_SUPPLY);

  /** Configure the main internal regulator output voltage
  */
  __HAL_PWR_VOLTAGESCALING_CONFIG(PWR_REGULATOR_VOLTAGE_SCALE0);

  while(!__HAL_PWR_GET_FLAG(PWR_FLAG_VOSRDY)) {}

  /** Configure LSE Drive Capability
  */
  HAL_PWR_EnableBkUpAccess();
  __HAL_RCC_LSEDRIVE_CONFIG(RCC_LSEDRIVE_LOW);

  /** Initializes the RCC Oscillators according to the specified parameters
  * in the RCC_OscInitTypeDef structure.
  */
  RCC_OscInitStruct.OscillatorType = RCC_OSCILLATORTYPE_HSE|RCC_OSCILLATORTYPE_LSE;
  RCC_OscInitStruct.HSEState = RCC_HSE_ON;
  RCC_OscInitStruct.LSEState = RCC_LSE_ON;
  RCC_OscInitStruct.PLL.PLLState = RCC_PLL_ON;
  RCC_OscInitStruct.PLL.PLLSource = RCC_PLLSOURCE_HSE;
  RCC_OscInitStruct.PLL.PLLM = 5;
  RCC_OscInitStruct.PLL.PLLN = 192;
  RCC_OscInitStruct.PLL.PLLP = 2;
  RCC_OscInitStruct.PLL.PLLQ = 4;
  RCC_OscInitStruct.PLL.PLLR = 2;
  RCC_OscInitStruct.PLL.PLLRGE = RCC_PLL1VCIRANGE_2;
  RCC_OscInitStruct.PLL.PLLVCOSEL = RCC_PLL1VCOWIDE;
  RCC_OscInitStruct.PLL.PLLFRACN = 0;
  if (HAL_RCC_OscConfig(&RCC_OscInitStruct) != HAL_OK)
  {
    Error_Handler();
  }

  /** Initializes the CPU, AHB and APB buses clocks
  */
  RCC_ClkInitStruct.ClockType = RCC_CLOCKTYPE_HCLK|RCC_CLOCKTYPE_SYSCLK
                              |RCC_CLOCKTYPE_PCLK1|RCC_CLOCKTYPE_PCLK2
                              |RCC_CLOCKTYPE_D3PCLK1|RCC_CLOCKTYPE_D1PCLK1;
  RCC_ClkInitStruct.SYSCLKSource = RCC_SYSCLKSOURCE_PLLCLK;
  RCC_ClkInitStruct.SYSCLKDivider = RCC_SYSCLK_DIV1;
  RCC_ClkInitStruct.AHBCLKDivider = RCC_HCLK_DIV2;
  RCC_ClkInitStruct.APB3CLKDivider = RCC_APB3_DIV2;
  RCC_ClkInitStruct.APB1CLKDivider = RCC_APB1_DIV2;
  RCC_ClkInitStruct.APB2CLKDivider = RCC_APB2_DIV2;
  RCC_ClkInitStruct.APB4CLKDivider = RCC_APB4_DIV2;

  if (HAL_RCC_ClockConfig(&RCC_ClkInitStruct, FLASH_LATENCY_4) != HAL_OK)
  {
    Error_Handler();
  }
}

 /* MPU Configuration */

void MPU_Config(void)
{
  MPU_Region_InitTypeDef MPU_InitStruct = {0};

  /* Disables the MPU */
  HAL_MPU_Disable();

  /** Initializes and configures the Region and the memory to be protected
  */
  MPU_InitStruct.Enable = MPU_REGION_ENABLE;
  MPU_InitStruct.Number = MPU_REGION_NUMBER0;
  MPU_InitStruct.BaseAddress = 0x20000000;
  MPU_InitStruct.Size = MPU_REGION_SIZE_128KB;
  MPU_InitStruct.SubRegionDisable = 0x0;
  MPU_InitStruct.TypeExtField = MPU_TEX_LEVEL0;
  MPU_InitStruct.AccessPermission = MPU_REGION_FULL_ACCESS;
  MPU_InitStruct.DisableExec = MPU_INSTRUCTION_ACCESS_ENABLE;
  MPU_InitStruct.IsShareable = MPU_ACCESS_NOT_SHAREABLE;
  MPU_InitStruct.IsCacheable = MPU_ACCESS_CACHEABLE;
  MPU_InitStruct.IsBufferable = MPU_ACCESS_BUFFERABLE;

  HAL_MPU_ConfigRegion(&MPU_InitStruct);

  /** Initializes and configures the Region and the memory to be protected
  */
  MPU_InitStruct.Number = MPU_REGION_NUMBER1;
  MPU_InitStruct.BaseAddress = 0x24000000;
  MPU_InitStruct.Size = MPU_REGION_SIZE_512KB;

  HAL_MPU_ConfigRegion(&MPU_InitStruct);

  /** Initializes and configures the Region and the memory to be protected
  */
  MPU_InitStruct.Number = MPU_REGION_NUMBER2;
  MPU_InitStruct.BaseAddress = 0x30000000;

  HAL_MPU_ConfigRegion(&MPU_InitStruct);

  /** Initializes and configures the Region and the memory to be protected
  */
  MPU_InitStruct.Number = MPU_REGION_NUMBER3;
  MPU_InitStruct.BaseAddress = 0x38000000;
  MPU_InitStruct.Size = MPU_REGION_SIZE_64KB;

  HAL_MPU_ConfigRegion(&MPU_InitStruct);

  /** Initializes and configures the Region and the memory to be protected
  */
  MPU_InitStruct.Number = MPU_REGION_NUMBER4;
  MPU_InitStruct.BaseAddress = 0x0;

  HAL_MPU_ConfigRegion(&MPU_InitStruct);

  /** Initializes and configures the Region and the memory to be protected
  */
  MPU_InitStruct.Number = MPU_REGION_NUMBER5;
  MPU_InitStruct.BaseAddress = 0xC0000000;
  MPU_InitStruct.Size = MPU_REGION_SIZE_32MB;

  HAL_MPU_ConfigRegion(&MPU_InitStruct);

  /** Initializes and configures the Region and the memory to be protected
  */
  MPU_InitStruct.Number = MPU_REGION_NUMBER6;
  MPU_InitStruct.BaseAddress = 0x08000000;
  MPU_InitStruct.Size = MPU_REGION_SIZE_2MB;

  HAL_MPU_ConfigRegion(&MPU_InitStruct);

  /** Initializes and configures the Region and the memory to be protected
  */
  MPU_InitStruct.Number = MPU_REGION_NUMBER7;
  MPU_InitStruct.BaseAddress = 0x90000000;
  MPU_InitStruct.Size = MPU_REGION_SIZE_8MB;

  HAL_MPU_ConfigRegion(&MPU_InitStruct);
  /* Enables the MPU */
  HAL_MPU_Enable(MPU_PRIVILEGED_DEFAULT);

}

void HAL_TIM_PeriodElapsedCallback(TIM_HandleTypeDef *htim)
{
  if (htim->Instance == TIM6)
  {
    HAL_IncTick();
  }
}

void Error_Handler(void)
{
  __disable_irq();
  while (1)
  {
  }
}

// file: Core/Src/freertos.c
/* USER CODE BEGIN Header */
/**
  ******************************************************************************
  * File Name          : freertos.c
  * Description        : Code for freertos applications
  ******************************************************************************
  * @attention
  *
  * Copyright (c) 2026 STMicroelectronics.
  * All rights reserved.
  *
  * This software is licensed under terms that can be found in the LICENSE file
  * in the root directory of this software component.
  * If no LICENSE file comes with this software, it is provided AS-IS.
  *
  ******************************************************************************
  */
/* USER CODE END Header */

#include "FreeRTOS.h"
#include "task.h"
#include "main.h"
#include "FreeRTOS.h"
#include "cmsis_os2.h"

/* USER CODE BEGIN Includes */

#include "MyCode.h"
#include "usbd_def.h"

/* USER CODE END Includes */

/* USER CODE BEGIN Variables */

float Vdda = 0.0f, Vbat = 0.0f, Temp = 0.0f;
TickType_t DetectObject_Tick_Start = 0, DetectObject_Tick_End = 0;         	// 用于保存当前的时间计数值
float DetectObject_FPS = 0.0f, LCD_Tick_FPS = 0.0f;
array_t* faces = NULL,  * eyes = NULL, * faceIDs = NULL;
Polygon poly = {0};
struct
{
  int n;
  Point* vertices;
} polyMessage = {0};

/* USER CODE END Variables */
/* Definitions for defaultTask */
osThreadId_t defaultTaskHandle;
const osThreadAttr_t defaultTask_attributes = {
  .name = "defaultTask",
  .stack_size = 128 * 4,
  .priority = (osPriority_t) osPriorityNormal,
};
/* Definitions for LCDRefresh */
osThreadId_t LCDRefreshHandle;
const osThreadAttr_t LCDRefresh_attributes = {
  .name = "LCDRefresh",
  .stack_size = 256 * 4,
  .priority = (osPriority_t) osPriorityNormal,
};
/* Definitions for LEDToggle */
osThreadId_t LEDToggleHandle;
const osThreadAttr_t LEDToggle_attributes = {
  .name = "LEDToggle",
  .stack_size = 128 * 4,
  .priority = (osPriority_t) osPriorityNormal,
};
/* Definitions for ImageProcess */
osThreadId_t ImageProcessHandle;
const osThreadAttr_t ImageProcess_attributes = {
  .name = "ImageProcess",
  .stack_size = 1024 * 4,
  .priority = (osPriority_t) osPriorityNormal,
};
/* Definitions for ObjectDetect */
osThreadId_t ObjectDetectHandle;
const osThreadAttr_t ObjectDetect_attributes = {
  .name = "ObjectDetect",
  .stack_size = 2048 * 4,
  .priority = (osPriority_t) osPriorityNormal,
};
/* Definitions for ADCSampling */
osThreadId_t ADCSamplingHandle;
const osThreadAttr_t ADCSampling_attributes = {
  .name = "ADCSampling",
  .stack_size = 128 * 4,
  .priority = (osPriority_t) osPriorityNormal,
};

void StartDefaultTask(void *argument);
void LCDRefreshTask(void *argument);
void LEDToggleTask(void *argument);
void ImageProcessTask(void *argument);
void ObjectDetectTask(void *argument);
void ADCSamplingTask(void *argument);

extern void MX_USB_DEVICE_Init(void);
void MX_FREERTOS_Init(void); /* (MISRA C 2004 rule 8.1) */

/* Hook prototypes */
void configureTimerForRunTimeStats(void);
unsigned long getRunTimeCounterValue(void);

/* USER CODE BEGIN 1 */
/* Functions needed when configGENERATE_RUN_TIME_STATS is on */
__weak void configureTimerForRunTimeStats(void)
{

}

__weak unsigned long getRunTimeCounterValue(void)
{
return 0;
}
/* USER CODE END 1 */

void MX_FREERTOS_Init(void) {

  /* Create the thread(s) */
  /* creation of defaultTask */
  defaultTaskHandle = osThreadNew(StartDefaultTask, NULL, &defaultTask_attributes);

  /* creation of LCDRefresh */
  LCDRefreshHandle = osThreadNew(LCDRefreshTask, NULL, &LCDRefresh_attributes);

  /* creation of LEDToggle */
  LEDToggleHandle = osThreadNew(LEDToggleTask, NULL, &LEDToggle_attributes);

  /* creation of ImageProcess */
  ImageProcessHandle = osThreadNew(ImageProcessTask, NULL, &ImageProcess_attributes);

  /* creation of ObjectDetect */
  ObjectDetectHandle = osThreadNew(ObjectDetectTask, NULL, &ObjectDetect_attributes);

  /* creation of ADCSampling */
  ADCSamplingHandle = osThreadNew(ADCSamplingTask, NULL, &ADCSampling_attributes);

}

void StartDefaultTask(void *argument)
{
  /* init code for USB_DEVICE */
  MX_USB_DEVICE_Init();
  /* USER CODE BEGIN StartDefaultTask */

  extern size_t umm_free_heap_size( void );
  extern size_t umm_max_free_block_size( void );
  extern int umm_usage_metric( void );
  extern int umm_fragmentation_metric( void );

  extern int basicPolyObjectNum;

  /* Infinite loop */
  for(;;)
  {
    TickType_t tick = xTaskGetTickCount();
    int8_t res;
    do
    {
      res = CDC_printf("[%d:%02d:%02d:%02d:%03d]\n"
                        "%d, %d, %d, %d\n"
                        "Vbat: %.3fV, Temp: %.3f^C, Vdda: %.3fV\n"
                        "In: %d, Out: %d\n"
                        "Face: %d, OD: %.3f\n"
                        "\n",
                        tick / 86400000, tick / 3600000 % 24, tick / 60000 % 60, tick / 1000 % 60, tick % 1000,
                        umm_free_heap_size(), umm_max_free_block_size(), umm_usage_metric(), umm_fragmentation_metric(),
                        Vbat, Temp, Vdda,
                        poly.objectNum, basicPolyObjectNum,
                        array_length(faceIDs), DetectObject_FPS);
      osDelay(20);
    }while(res != USBD_OK);

    osDelay(1000 / 2); // ~2fps
  }
  /* USER CODE END StartDefaultTask */
}

void LCDRefreshTask(void *argument)
{
  /* USER CODE BEGIN LCDRefreshTask */
  extern size_t umm_free_heap_size( void );
  extern size_t umm_max_free_block_size( void );
  extern int umm_usage_metric( void );
  extern int umm_fragmentation_metric( void );

  extern uint16_t* pCamera_Image;
  extern __IO float OV5640_FPS ;      // 帧率
  extern uint16_t LCD_Buff[LCD_Height][LCD_Width];
  extern uint16_t LCDBackImage[LCD_Height][LCD_Width];

  extern int basicPolyObjectNum;

  SPI_LCD_Init();

  /* Infinite loop */
  for(;;)
  {
    // 计算LCD刷新帧率
    static TickType_t LCD_Tick_Start = 0, LCD_Tick_End = 0;

    LCD_Tick_End = xTaskGetTickCount();
    LCD_Tick_FPS = 1000.0f / (LCD_Tick_End - LCD_Tick_Start);
    LCD_Tick_Start = LCD_Tick_End;

    image_t srcImg, midImg, dstImg;
    STM32Ipl_Init(&srcImg, Display_Width, Display_Height, IMAGE_BPP_RGB565, (uint8_t*)pCamera_Image);
    STM32Ipl_Init(&midImg, LCD_Height, LCD_Width, IMAGE_BPP_RGB565, (uint8_t*)LCDBackImage);
    STM32Ipl_Init(&dstImg, LCD_Height, LCD_Width, IMAGE_BPP_RGB565, (uint8_t*)LCD_Buff);
    // STM32Ipl_Resize(&srcImg, &dstImg, RESIZE_NEAREST);  // 将图像缩放到LCD分辨率，等价于LCD_ShowImage
    DMA2D_MemCopy_OS(srcImg.data, midImg.data, midImg.w, midImg.h, 0, 0, DMA2D_INPUT_RGB565);

    for (int i = 0; i < poly.n; ++i)
    {
      int n = poly.n;
      const Point* v = poly.vertices;
      const Point* a = &v[i];
      const Point* b = &v[(i + 1) % n];  // 边 a->b
      point_t _a = {.x = (int16_t)(a->x * LCD_Height), .y = (int16_t)(a->y * LCD_Width)};
      point_t _b = {.x = (int16_t)(b->x * LCD_Height), .y = (int16_t)(b->y * LCD_Width)};
      STM32Ipl_DrawLine(&midImg, &_a, &_b, STM32IPL_COLOR_GREEN, 1);
    }

    // for (int i = 0; i < array_length(faces); i++) // 一定要实时读faceIDs的状态，防止其他任务更改faceIDs的状态导致未定义行为
    // {
    //   faceObject_t *f = array_at(faces, i);
    //   // Draw the bounding box around each detected face.
    //   // uint16_t x = f->r.x * LCD_Height - (LCD_Height - LCD_Width) / 2;
    //   // uint16_t y = f->r.y * LCD_Height;
    //   // uint16_t w = f->r.width * LCD_Height;
    //   // uint16_t h = f->r.height * LCD_Height;
    //   uint16_t x = f->rect.x * LCD_Height;
    //   uint16_t y = f->rect.y * LCD_Width;
    //   uint16_t w = f->rect.width * LCD_Height;
    //   uint16_t h = f->rect.height * LCD_Width;
    //   STM32Ipl_DrawRectangle(&midImg, x, y, w, h, STM32IPL_COLOR_GREEN, 2, false);
    //   // STM32Ipl_DrawCircle(&midImg, (uint16_t)(f->point.x * LCD_Height), (uint16_t)(f->point.y * LCD_Width), 4, f->color, 1, 1);
    // }

    for (int i = 0; i < array_length(faceIDs); i++) // 一定要实时读faceIDs的状态，防止其他任务更改faceIDs的状态导致未定义行为
    {
      faceIDObject_t *f = array_at(faceIDs, i);
      // Draw the bounding box around each detected face.
      // uint16_t x = f->r.x * LCD_Height - (LCD_Height - LCD_Width) / 2;
      // uint16_t y = f->r.y * LCD_Height;
      // uint16_t w = f->r.width * LCD_Height;
      // uint16_t h = f->r.height * LCD_Height;
      uint16_t x = f->r.x * LCD_Height;
      uint16_t y = f->r.y * LCD_Width;
      uint16_t w = f->r.width * LCD_Height;
      uint16_t h = f->r.height * LCD_Width;
      stm32ipl_color_t color = f->color;
      STM32Ipl_DrawRectangle(&midImg, x, y, w, h, color, 2, false);
      STM32Ipl_DrawCircle(&midImg, (uint16_t)(f->point.x * LCD_Height), (uint16_t)(f->point.y * LCD_Width), 4, f->color, 1, 1);
    }

    STM32Ipl_Rotation270(&dstImg, &midImg);

    // for (int i = 0; i < array_length(faces); i++) // 一定要实时读faceIDs的状态，防止其他任务更改faceIDs的状态导致未定义行为
    // {
    //   faceObject_t *f = array_at(faces, i);
    //   uint16_t x = f->rect.x * LCD_Height;
    //   uint16_t y = f->rect.y * LCD_Width;
    //   uint16_t w = f->rect.width * LCD_Height;
    //   uint16_t h = f->rect.height * LCD_Width;
    //   LCD_printf(y / 12, (x + w) / 6, "%.2f", f->prob);
    // }

    for (int i = 0; i < array_length(faceIDs); i++) // 一定要实时读faceIDs的状态，防止其他任务更改faceIDs的状态导致未定义行为
    {
      faceIDObject_t *f = array_at(faceIDs, i);
      uint16_t x = f->r.x * LCD_Height;
      uint16_t y = f->r.y * LCD_Width;
      uint16_t w = f->r.width * LCD_Height;
      uint16_t h = f->r.height * LCD_Width;
      LCD_printf(y / 12, x / 6, "%d", f->id);
      LCD_printf(y / 12, (x + w) / 6, "%.2f", f->score);
      LCD_printf((y + h) / 12, (x + w) / 6, "%d", f->zone);
    }

    // LCD_Clear();
    // LCD_ShowImage(0, 0, (uint16_t *)LCDBackImage);  // 将图像数据复制到屏幕
    // LCD_ShowImage(0, 0, (uint16_t *)pCamera_Image);  // 将图像数据复制到屏幕
    // LCD_printf(16, 1,"%d, %d, %d, %d", umm_free_heap_size(), umm_max_free_block_size(), umm_usage_metric(), umm_fragmentation_metric());
    // LCD_printf(7, 1, "Time: %d:%02d:%02d:%02d:%03d", LCD_Tick_End / 86400000, LCD_Tick_End / 3600000 % 24, LCD_Tick_End / 60000 % 60, LCD_Tick_End / 1000 % 60, LCD_Tick_End % 1000);
    // LCD_printf(18, 1, "Vbat: %.3fV, Temp: %.3f^C, Vdda: %.3fV", Vbat, Temp, Vdda);
    LCD_printf(18, 1, "In: %d, Out: %d", poly.objectNum, basicPolyObjectNum);
    LCD_printf(19, 1,  "Face: %d, Scr: %.3f, Cam: %.3f, OD: %.3f", array_length(faceIDs), LCD_Tick_FPS, OV5640_FPS, DetectObject_FPS);
    LCD_SPI_Transmit();

    // uint32_t dstSize = JPEGEncode((uint8_t*)LCD_Buff, LCD_Height * LCD_Width * 2);
    // CDC_Transmit_FS(jpeg_buffer, dstSize);

    osDelayUntil(LCD_Tick_End + 1000 / 10); // ~10fps
  }
  /* USER CODE END LCDRefreshTask */
}

void LEDToggleTask(void *argument)
{
  /* USER CODE BEGIN LEDToggleTask */
  /* Infinite loop */
  for(;;)
  {
    HAL_GPIO_TogglePin(LED_GPIO_Port, LED_Pin);
    osDelayUntil(xTaskGetTickCount() / 1000 * 1000 + 1000);
  }
  /* USER CODE END LEDToggleTask */
}

void ImageProcessTask(void *argument)
{
  /* USER CODE BEGIN ImageProcessTask */

  extern CDC_Receive_t CDC_Receive;
  extern uint16_t* pCamera_Image; // 摄像头数据缓冲区指针
  extern uint16_t LCD_Buff[LCD_Height][LCD_Width];
  extern uint8_t LCD_SPI_LOCKED;
  extern uint8_t UserTxBufferFS[APP_TX_DATA_SIZE];

  JPEGEncodeInit();

  /* Infinite loop */
  for(;;)
  {
    if(CDC_Receive.received)  // 等待一帧数据传输完成
    {
      CDC_Receive.received = 0;
      uint8_t* Buf = CDC_Receive.Buf;
      uint32_t Len = CDC_Receive.Len;
      char* s_jpeg = "jpeg";
      char* s_uid = "uid";
      char* s_area = "area";

      if(strncmp(Buf, s_jpeg, strlen(s_jpeg)) == 0)
      {
        while(LCD_SPI_LOCKED != 1) osThreadYield(); // 等待一帧数据传输完成

        uint32_t dstSize = JPEGEncode((uint8_t*)LCD_Buff, Display_Height * Display_Width * 2);
        while(CDC_Transmit_FS(jpeg_buffer, dstSize) != USBD_OK) osThreadYield();
      }
      else if(strncmp(Buf, s_uid, strlen(s_uid)) == 0)
      {
        while(CDC_printf("uid: %08X %08X %08X\n", HAL_GetUIDw0(), HAL_GetUIDw1(), HAL_GetUIDw2()) != USBD_OK) osThreadYield();
      }
      else if(strncmp(Buf, s_area, strlen(s_area)) == 0)
      {
        int n = *(int*)(Buf + 4);
        // float* pf = (float*)(Buf + 8);
        // float sum = 0.0f;
        // for(int i = 0; i < n * 2; i++)
        // {
        //   sum += *pf++;
        // }
        // if(fabsf(sum - *pf) <= 1e-6)
        if(n < 256)
        {
          // send to poly
          if(polyMessage.n == 0 && polyMessage.vertices == NULL) // 判断消息是否被其它任务接收
          {
            Point* vertices = (Point*)xalloc(sizeof(Point) * n);
            if(vertices != NULL)
            {
              memcpy(vertices, Buf + 8, sizeof(Point) * n);
              polyMessage.vertices = vertices;
              polyMessage.n = n;
            }
          }
        }
      }
      else
      {
        memcpy(UserTxBufferFS, Buf, Len);
        while(CDC_Transmit_FS(UserTxBufferFS, Len) != USBD_OK) osThreadYield();
      }
    }
    else
    {
      osThreadYield();
    }
  }
  /* USER CODE END ImageProcessTask */
}

void ObjectDetectTask(void *argument)
{
  /* USER CODE BEGIN ObjectDetectTask */

  extern OV5640_FrameState ov5640_FrameState;
  extern uint16_t* pCamera_Image; // 摄像头数据缓冲区指针
  extern void xfree(void *mem);

	DCMI_OV5640_Init();   			 	// DCMI以及OV5640初始化
	OV5640_AF_Download_Firmware();	// 写入自动对焦固件
	OV5640_AF_Trigger_Constant();		// 自动对焦 ，持续 触发，当OV5640检测到当前画面不在焦点时，会一直触发对焦
  OV5640_StartImageCapture();

  static Point test_vertices[] = {{0.440625f, 0.2791666666666667f},
                      {0.440625f, 0.8333333333333334f},
                      {0.41875f, 0.9041666666666667f},
                      {0.659375f, 0.9f},
                      {0.609375f, 0.8416666666666667f},
                      {0.6f, 0.2791666666666667f},
  };
  extern int basicPolyObjectNum;

  PolygonInit(&poly, test_vertices, sizeof(test_vertices) / sizeof(Point), 1);
  Point* vertices = test_vertices; // 存取现在导入Poly的vertices

  array_alloc(&faces, xfree);
  array_alloc(&eyes, xfree);
  array_alloc(&faceIDs, xfree);

  STM32CubeAI_Studio_AI_Init();

  /* Infinite loop */
  for(;;)
  {
    if(ov5640_FrameState.objectDetectState)  // 等待一帧数据传输完成
    {
      ov5640_FrameState.objectDetectState = 0;

      // 计算帧率
      DetectObject_Tick_End = xTaskGetTickCount();
			DetectObject_FPS = 1000.0f / (DetectObject_Tick_End - DetectObject_Tick_Start);
			DetectObject_Tick_Start = DetectObject_Tick_End;

      STM32CubeAI_Studio_AI_Process();

      HAL_GPIO_WritePin(GPIOA, GPIO_PIN_8, basicPolyObjectNum > 0);

      if(polyMessage.n > 0 && polyMessage.vertices != NULL)
      {
        PolygonDelete(&poly);
        if(vertices != test_vertices)
        {
          xfree(vertices);
          poly.vertices = NULL;
        }
        PolygonInit(&poly, polyMessage.vertices, polyMessage.n, 1);
        // 对polyMessage消息清零，通知消息已接收
        polyMessage.n = 0;
        polyMessage.vertices = NULL;

        vertices = polyMessage.vertices;
      }

    }
    else
    {
      osThreadYield();
    }
  }
  /* USER CODE END ObjectDetectTask */
}

void ADCSamplingTask(void *argument)
{
  /* USER CODE BEGIN ADCSamplingTask */

  __attribute__((section(".ram_d3_bss"))) __IO static struct {uint16_t Vbat, Temp, Vref;} adcval = {0};

  HAL_ADCEx_Calibration_Start(&hadc3, ADC_CALIB_OFFSET_LINEARITY, ADC_SINGLE_ENDED);
  HAL_ADC_Start_DMA(&hadc3, (uint32_t*)&adcval, sizeof(adcval) / sizeof(uint16_t));

  float vrefint_cal_vref = (VREFINT_CAL_VREF / 1000.0f);
  float temperature_cal1_temp = TEMPSENSOR_CAL1_TEMP;
  float temperature_cal2_temp = TEMPSENSOR_CAL2_TEMP;
  float vrefint_cal_addr = (*VREFINT_CAL_ADDR);
  float tempsensor_cal1_addr = (*TEMPSENSOR_CAL1_ADDR);
  float tempsensor_cal2_addr = (*TEMPSENSOR_CAL2_ADDR);

  /* Infinite loop */
  for(;;)
  {
    TickType_t tick = xTaskGetTickCount();

    Vdda = vrefint_cal_vref * vrefint_cal_addr / adcval.Vref;
    Vbat = adcval.Vbat * Vdda / (float)(1 << 16) * 4.0f;
    Temp = temperature_cal1_temp
                        + (adcval.Temp / vrefint_cal_vref * Vdda - tempsensor_cal1_addr)
                            * (temperature_cal2_temp - temperature_cal1_temp)
                            / (tempsensor_cal2_addr - tempsensor_cal1_addr);

    osDelayUntil(tick + 1000/10);
  }
  /* USER CODE END ADCSamplingTask */
}
